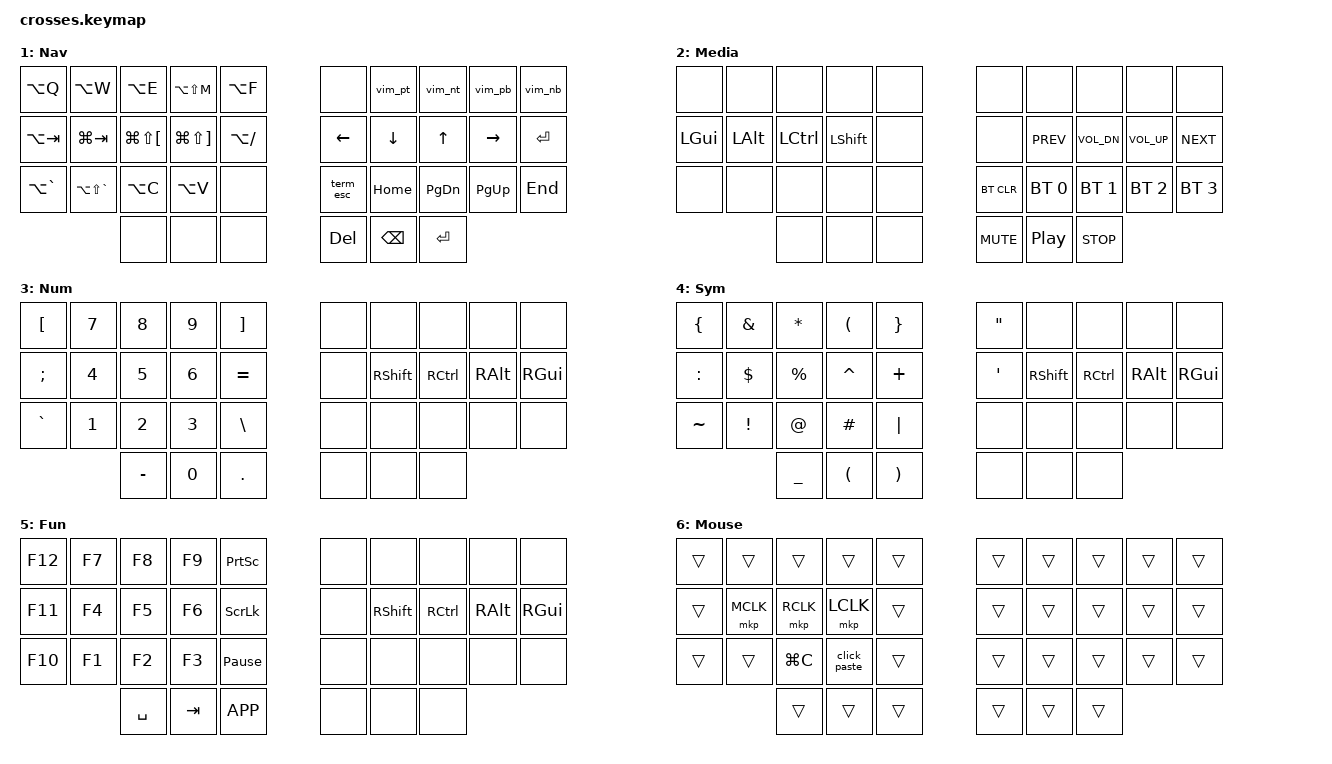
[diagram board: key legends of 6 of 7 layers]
/*
 * Miryoku QWERTY layout for Crosses35 — ported from timb's Corne-ish Zen v2
 *
 * Layout: SGCA home row mods (SHIFT, CTRL, ALT, GUI pinky→index) — matches Ergodox
 * Alphas: QWERTY
 * Custom: J+K combo → ESC, vim macros merged into NAV layer
 * Behaviors: positional home row mods (bilateral), retro-tap thumb layer-taps
 *
 * Dual trackball:
 *   Left  = scroll (zip_xy_to_scroll_mapper in shield overlay)
 *   Right = mouse cursor (direct in shield overlay)
 *   MOUSE layer (6) provides click buttons via thumb keys
 *
 * 36-key Crosses matrix:
 *  ╭──────┬──────┬──────┬──────┬──────╮    ╭──────┬──────┬──────┬──────┬──────╮
 *  │  0   │  1   │  2   │  3   │  4   │    │  5   │  6   │  7   │  8   │  9   │
 *  ├──────┼──────┼──────┼──────┼──────┤    ├──────┼──────┼──────┼──────┼──────┤
 *  │  10  │  11  │  12  │  13  │  14  │    │  15  │  16  │  17  │  18  │  19  │
 *  ├──────┼──────┼──────┼──────┼──────┤    ├──────┼──────┼──────┼──────┼──────┤
 *  │  20  │  21  │  22  │  23  │  24  │    │  25  │  26  │  27  │  28  │  29  │
 *  ╰──────┴──────┴──────┼──────┼──────┤    ├──────┼──────┼──────┴──────┴──────╯
 *                       │  30  │  31  │    │  32  │  33  │
 *                       ╰──────┼──────┤    ├──────┼──────╯
 *                              │  32  │    │  35  │
 *                              ╰──────╯    ╰──────╯
 *
 * Layer map:
 *   0 BASE    QWERTY + SGCA home row mods
 *   1 NAV     ← left inner thumb hold — arrows, AeroSpace, vim macros
 *   2 MEDIA   ← left outer thumb hold — media, bluetooth
 *   3 NUM     ← right mid thumb hold  — numpad on left hand
 *   4 SYM     ← right inner thumb hold — symbols on left hand
 *   5 FUN     ← right outer thumb hold — F-keys on left hand
 *   6 MOUSE   ← auto-activates on trackball movement (+ Z/SLASH hold fallback)
 *
 * Thumb cluster (left → right):
 *   Left:  ESC/MEDIA | TAB/GUI | SPC/NAV
 *   Right: ENT/SYM   | BSPC/NUM | DEL/FUN
 *
 * NOTE: Home row mod order is SGCA (SHIFT on pinky, GUI on index),
 * matching your Ergodox. To switch to Miryoku GACS, swap the HRML/HRMR macros below.
 */

#include <behaviors.dtsi>
#include <dt-bindings/zmk/bt.h>
#include <dt-bindings/zmk/keys.h>
#include <dt-bindings/zmk/pointing.h>
#include <input/processors.dtsi>

/ {
    chosen {
        zmk,physical-layout = &gggw_crosses_36_layout;
    };

    /* Auto mouse layer: trackball movement activates MOUSE layer (6),
     * deactivates after 2s of no movement.
     * require-prior-idle-ms: don't activate if typing happened < 500ms ago
     * excluded-positions: thumb keys (mouse buttons) don't deactivate the layer */
    auto_mouse_layer: auto_mouse_layer {
        compatible = "zmk,input-processor-temp-layer";
        #input-processor-cells = <2>;
        require-prior-idle-ms = <500>;
        excluded-positions = <11 12 13 22 23>;
    };
};

/* Override the right trackball listener to add auto mouse layer.
 * The shield overlay sets: input-processors = <&zip_ble_report_rate_limit>;
 * We prepend the auto mouse layer processor. */
&trackball_central_listener {
    input-processors = <&auto_mouse_layer 6 2000>, <&zip_ble_report_rate_limit>;
};

#define BASE  0
#define NAV   1
#define MEDIA 2
#define NUM   3
#define SYM   4
#define FUN   5
#define MOUSE 6

// SGCA: SHIFT, CTRL, ALT, GUI (pinky → index) — matches Ergodox
// Uses positional hold-tap: opposite-hand keypresses always trigger the hold (modifier)
#define HRML(k1, k2, k3, k4) &hm_l LSHFT k1  &hm_l LCTRL k2  &hm_l LALT k3  &hm_l LGUI k4
#define HRMR(k1, k2, k3, k4) &hm_r RGUI k1  &hm_r RALT k2  &hm_r RCTRL k3  &hm_r RSHFT k4

/ {
    behaviors {
        // Left-hand home row mods: right-hand keys (+ right thumbs) trigger hold
        hm_l: homerow_mod_left {
            compatible = "zmk,behavior-hold-tap";
            #binding-cells = <2>;
            tapping-term-ms = <200>;
            quick-tap-ms = <120>;
            require-prior-idle-ms = <150>;
            flavor = "balanced";
            bindings = <&kp>, <&kp>;
            hold-trigger-key-positions = <5 6 7 8 9  15 16 17 18 19  25 26 27 28 29  33 34 35>;
            hold-trigger-on-release;
        };

        // Right-hand home row mods: left-hand keys (+ left thumbs) trigger hold
        hm_r: homerow_mod_right {
            compatible = "zmk,behavior-hold-tap";
            #binding-cells = <2>;
            tapping-term-ms = <200>;
            quick-tap-ms = <120>;
            require-prior-idle-ms = <150>;
            flavor = "balanced";
            bindings = <&kp>, <&kp>;
            hold-trigger-key-positions = <0 1 2 3 4  10 11 12 13 14  20 21 22 23 24  30 31 32>;
            hold-trigger-on-release;
        };

        // Layer-tap with retro-tap: hold-then-release without pressing another key still sends tap
        lt_ret: layer_tap_retro {
            compatible = "zmk,behavior-hold-tap";
            #binding-cells = <2>;
            tapping-term-ms = <200>;
            quick-tap-ms = <150>;
            flavor = "balanced";
            retro-tap;
            bindings = <&mo>, <&kp>;
        };
    };

    macros {
        // Click + paste: left-click then ⌘V
        click_paste: click_paste {
            compatible = "zmk,behavior-macro";
            #binding-cells = <0>;
            wait-ms = <30>;
            tap-ms = <30>;
            bindings = <&mkp LCLK &kp LG(V)>;
        };

        // Escape nvim terminal mode: Ctrl+\ Ctrl+n
        term_esc: term_esc {
            compatible = "zmk,behavior-macro";
            #binding-cells = <0>;
            wait-ms = <30>;
            tap-ms = <30>;
            bindings = <&kp LC(BSLH) &kp LC(N)>;
        };

        // Vim previous tab: Ctrl+\ Ctrl+n [t
        vim_pt: vim_pt {
            compatible = "zmk,behavior-macro";
            #binding-cells = <0>;
            wait-ms = <30>;
            tap-ms = <30>;
            bindings = <&kp LC(BSLH) &kp LC(N) &kp LBKT &kp T>;
        };

        // Vim next tab: Ctrl+\ Ctrl+n ]t
        vim_nt: vim_nt {
            compatible = "zmk,behavior-macro";
            #binding-cells = <0>;
            wait-ms = <30>;
            tap-ms = <30>;
            bindings = <&kp LC(BSLH) &kp LC(N) &kp RBKT &kp T>;
        };

        // Vim previous buffer: Ctrl+\ Ctrl+n [b
        vim_pb: vim_pb {
            compatible = "zmk,behavior-macro";
            #binding-cells = <0>;
            wait-ms = <30>;
            tap-ms = <30>;
            bindings = <&kp LC(BSLH) &kp LC(N) &kp LBKT &kp B>;
        };

        // Vim next buffer: Ctrl+\ Ctrl+n ]b
        vim_nb: vim_nb {
            compatible = "zmk,behavior-macro";
            #binding-cells = <0>;
            wait-ms = <30>;
            tap-ms = <30>;
            bindings = <&kp LC(BSLH) &kp LC(N) &kp RBKT &kp B>;
        };
    };

    combos {
        compatible = "zmk,combos";

        // J + K = Escape (ported from Ergodox)
        combo_esc {
            timeout-ms = <50>;
            key-positions = <16 17>; // J(pos 16) + K(pos 17)
            bindings = <&kp ESC>;
            layers = <BASE>;
        };
    };

    keymap {
        compatible = "zmk,keymap";

        /* 0: BASE — QWERTY + SGCA home row mods
         * ╭──────┬──────┬──────┬──────┬──────╮    ╭──────┬──────┬──────┬──────┬──────╮
         * │  Q   │  W   │  E   │  R   │  T   │    │  Y   │  U   │  I   │  O   │  P   │
         * ├──────┼──────┼──────┼──────┼──────┤    ├──────┼──────┼──────┼──────┼──────┤
         * │ A/SFT│ S/CTL│ D/ALT│ F/GUI│  G   │    │  H   │ J/GUI│ K/ALT│ L/CTL│ ;/SFT│
         * ├──────┼──────┼──────┼──────┼──────┤    ├──────┼──────┼──────┼──────┼──────┤
         * │Z/MSE │  X   │  C   │  V   │  B   │    │  N   │  M   │  ,   │  .   │//MSE │
         * ╰──────┴──────┴──────┼──────┼──────┤    ├──────┼──────┼──────┴──────┴──────╯
         *                      │SPC   │TAB   │    │BSPC  │DEL   │
         *                      │NAV   │GUI/TB│    │NUM   │FUN   │
         *                      ╰──────┼──────┤    ├──────┼──────╯
         *                             │ESC   │    │ENT   │
         *                             │MEDIA │    │SYM   │
         *                             ╰──────╯    ╰──────╯
         */
        base_layer {
            display-name = "Base";
            bindings = <
&kp Q             &kp W          &kp E           &kp R           &kp T              &kp Y           &kp U           &kp I           &kp O          &kp P
HRML(A,               S,              D,              F)          &kp G              &kp H           HRMR(J,              K,              L,             SEMI)
&lt MOUSE Z       &kp X          &kp C           &kp V           &kp B              &kp N           &kp M           &kp COMMA       &kp DOT        &lt MOUSE FSLH
                                 &lt_ret NAV SPACE &hm_l LGUI TAB &lt_ret MEDIA ESC  &lt_ret FUN DEL &lt_ret NUM BSPC &lt_ret SYM RET
            >;
        };

        /* 1: NAV — arrows, AeroSpace, vim macros */
        nav_layer {
            display-name = "Nav";
            bindings = <
&kp LA(Q)        &kp LA(W)      &kp LA(E)       &kp LA(LS(M))   &kp LA(F)          &none           &vim_pt         &vim_nt         &vim_pb        &vim_nb
&kp LA(TAB)      &kp LG(TAB)    &kp LG(LS(LBKT)) &kp LG(LS(RBKT)) &kp LA(FSLH)     &kp LEFT        &kp DOWN        &kp UP          &kp RIGHT      &kp RET
&kp LA(GRAVE)    &kp LA(LS(GRAVE)) &kp LA(C)    &kp LA(V)       &none              &term_esc       &kp HOME        &kp PG_DN       &kp PG_UP      &kp END
                                 &none           &none           &none              &kp DEL         &kp BSPC        &kp RET
            >;
        };

        /* 2: MEDIA — playback + bluetooth */
        media_layer {
            display-name = "Media";
            bindings = <
&none            &none          &none           &none           &none              &none           &none           &none           &none          &none
&kp LGUI         &kp LALT       &kp LCTRL       &kp LSHFT       &none              &none           &kp C_PREV      &kp C_VOL_DN    &kp C_VOL_UP   &kp C_NEXT
&none            &none          &none           &none           &none              &bt BT_CLR      &bt BT_SEL 0    &bt BT_SEL 1    &bt BT_SEL 2   &bt BT_SEL 3
                                &none           &none           &none              &kp C_MUTE      &kp C_PP        &kp C_STOP
            >;
        };

        /* 3: NUM — numpad on left hand, bare mods on right */
        num_layer {
            display-name = "Num";
            bindings = <
&kp LBKT         &kp N7         &kp N8          &kp N9          &kp RBKT           &none           &none           &none           &none          &none
&kp SEMI         &kp N4         &kp N5          &kp N6          &kp EQUAL          &none           &kp RSHFT       &kp RCTRL       &kp RALT       &kp RGUI
&kp GRAVE        &kp N1         &kp N2          &kp N3          &kp BSLH           &none           &none           &none           &none          &none
                                &kp MINUS       &kp N0          &kp DOT            &none           &none           &none
            >;
        };

        /* 4: SYM — symbols on left hand, bare mods + quotes on right */
        sym_layer {
            display-name = "Sym";
            bindings = <
&kp LBRC         &kp AMPS       &kp ASTRK       &kp LPAR        &kp RBRC           &kp DQT         &none           &none           &none          &none
&kp COLON        &kp DLLR       &kp PRCNT       &kp CARET       &kp PLUS           &kp SQT         &kp RSHFT       &kp RCTRL       &kp RALT       &kp RGUI
&kp TILDE        &kp EXCL       &kp AT          &kp HASH        &kp PIPE           &none           &none           &none           &none          &none
                                &kp UNDER       &kp LPAR        &kp RPAR           &none           &none           &none
            >;
        };

        /* 5: FUN — function keys on left hand, bare mods on right */
        fun_layer {
            display-name = "Fun";
            bindings = <
&kp F12          &kp F7         &kp F8          &kp F9          &kp PSCRN          &none           &none           &none           &none          &none
&kp F11          &kp F4         &kp F5          &kp F6          &kp SLCK           &none           &kp RSHFT       &kp RCTRL       &kp RALT       &kp RGUI
&kp F10          &kp F1         &kp F2          &kp F3          &kp PAUSE_BREAK    &none           &none           &none           &none          &none
                                &kp SPACE       &kp TAB         &kp K_APP          &none           &none           &none
            >;
        };

        /* 6: MOUSE — trackball click buttons (hold Z or /)
         * Left thumb:  MCLK  LCLK  RCLK
         * Right thumb: RCLK  LCLK  MCLK
         */
        /* 6: MOUSE — auto-activates on trackball movement
         * S=MCLK  D=RCLK  F=LCLK  (left home row for right-hand trackball)
         * Thumbs also have clicks as fallback */
        mouse_layer {
            display-name = "Mouse";
            bindings = <
&trans           &trans         &trans          &trans          &trans             &trans          &trans          &trans          &trans         &trans
&trans           &mkp MCLK      &mkp RCLK       &mkp LCLK       &trans             &trans          &trans          &trans          &trans         &trans
&trans           &trans         &kp LG(C)       &click_paste    &trans             &trans          &trans          &trans          &trans         &trans
                                &trans          &trans          &trans             &trans          &trans          &trans
            >;
        };
    };
};
